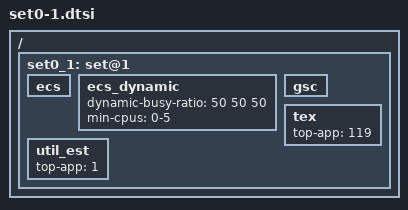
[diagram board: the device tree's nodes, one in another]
/ {
	/* normal mode - touch boost */
	set0_1: set@1 {
		ecs { };

		ecs_dynamic {
			dynamic-busy-ratio	= <50 50 50>;
			min-cpus = "0-5";
		};

		gsc { };

		tex {
			top-app = <119>;
		};

		util_est {
			top-app	= <1>;
		};
	};
};
